# RZN2L register map
Vendor: Renesas Electronics Corporation; Series: RZN; File version: 1.30.01
CPU: other r0p0, little endian, MPU, no FPU, VTOR, 4 interrupt priority bits, 624 interrupts
Registers are 32-bit, read-write, reset 0x0 unless marked. A register's access mark holds for its fields unless they carry their own. Offsets are from the block's base; [hi:lo] are bit positions; {n}, {i} and the like mark numbered series; 'fields as' and 'values as' point back to an identical list.

## SYSRAM_CTL — System SRAM Control
Base 0x81281800
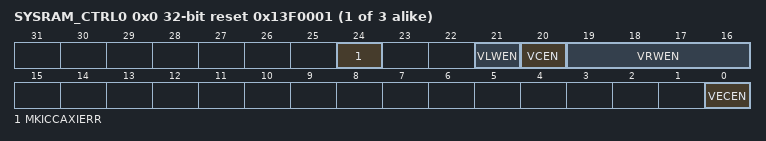
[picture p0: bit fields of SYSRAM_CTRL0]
{0x0+0x10*i} SYSRAM_CTRL{i} (i=0..2) reset 0x13F0001 — System SRAM Control Register {i}
  [24] MKICCAXIERR — Controls AXI-SLVERR issuance for ECC 2-bit errors
    0=Issue AXI-SLEVER; 1=Do not issue AXI-SLEVER
  [21] VLWEN — Enables write for RAM
    0=Disabled; 1=Enabled
  [20] VCEN — Enables access to RAM
    0=Disabled; 1=Enabled
  [19:16] VRWEN — Enables write for each page of RAM
    0=Disabled; 1=Enabled
  [0] VECEN — Enables or disables error correction with ECC
    0=Disabled; 1=Enabled

## SHOSTIF_CFG — Serial Host Interface Configuration
Base 0x81281920
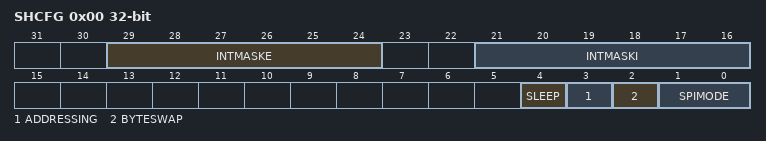
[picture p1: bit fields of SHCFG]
0x00 SHCFG — SHOSTIF Configuration Register
  [29:24] INTMASKE — Interrupt Mask Enable for External Interrupt (HSPI_INT# signal)
    0=No masked; 1=Masked
  [21:16] INTMASKI — Interrupt Mask Enable for Internal Interrupt (SHOST_INT)
    0=No masked; 1=Masked
  [4] SLEEP ro — SHOSTIF Enable Flag Monitor
    0=Not safe to stop the internal clock; 1=Safe to stop the internal clock
  [3] ADDRESSING — Addressing Mode
    0=32-bit; 1=8-bit
  [2] BYTESWAP — Byte Swap Mode
    0=No byte swap. Use this setting if byte order of data input by SPI master is [31:24], [23:16], [15:8], or [7:0].; 1=Byte swap. Use this setting if byte order of data input by SPI master is [7:0], [15:8], [23:16], or [31:24].
  [1:0] SPIMODE — SPI Frame Format Select
    0=Standard SPI mode; 1=SPI Dual mode; 2=SPI Quad mode; 3=SPI Octal mode

## PHOSTIF_CFG — Parallel Host Interface Configuration
Base 0x81281930
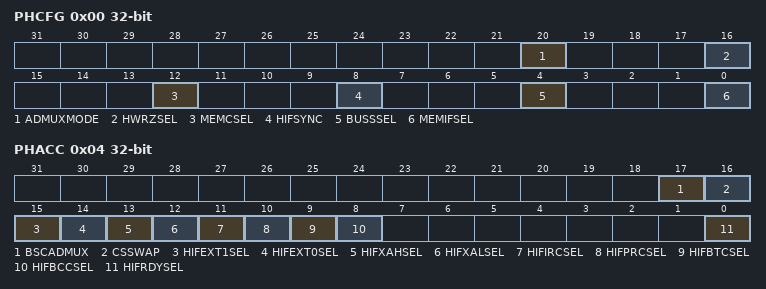
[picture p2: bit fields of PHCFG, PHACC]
0x00 PHCFG — PHOSTIF Configureation Register
  [20] ADMUXMODE
  [16] HWRZSEL
    0=HWRSTB# is write strobe and HWR[1:0] is byte write enable; 1=HWR[1:0]# is byte write strobe. HWRSTB# is not referred.
  [12] MEMCSEL
    0=Synchronous/Asynchronous SRAM interface mode; 1=Synchronous burst SRAM type transfer mode
  [8] HIFSYNC
  [4] BUSSSEL
    0=8-bit bus width; 1=16-bit bus width
  [0] MEMIFSEL
    0=Disables PHOSTIF; 1=Enables PHOSTIF
0x04 PHACC — PHOSTIF Register Access Control Register
  [17] BSCADMUX
    0=Disables; 1=Enables
  [16] CSSWAP
    0=Not swapped; 1=Swapped. HCS0# pin works as HCS1# function and HCS1# pin works as HCS0# function.
  [15] HIFEXT1SEL
    0=Read only; 1=Read and Write
  [14] HIFEXT0SEL
    0=Read only; 1=Read and Write
  [13] HIFXAHSEL
    0=Read only; 1=Read and Write
  [12] HIFXALSEL
    0=Read only; 1=Read and Write
  [11] HIFIRCSEL
    0=Read only; 1=Read and Write
  [10] HIFPRCSEL
    0=Read only; 1=Read and Write
  [9] HIFBTCSEL
    0=Read only; 1=Read and Write
  [8] HIFBCCSEL
    0=Read only; 1=Read and Write
  [0] HIFRDYSEL
    0=HIFRDY bit in HIFMON1 register indicates 0 after PHOSTIF module reset is released. Internal CPU must write 1 to HIFRDY bit in the HIFMON1 register after initial setting of PHOSTIF is completed by internal CPU.; 1=HIFRDY bit in HIFMON1 register indicates 1 after PHOSTIF module reset is released

## RWP_S — Register Write Protection for Safety Area
Base 0x81281A00
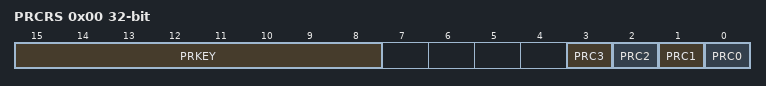
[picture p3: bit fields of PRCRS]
0x00 PRCRS — Safety Area Protect Register
  [15:8] PRKEY wo — PRC Key Code
  [n] PRC{n} (n=0..3) — Protect {n}
    0=Write disabled; 1=Write enabled

## MTU_NF — Multi-Function Timer Pulse Unit Noise Filter
Base 0x90001290
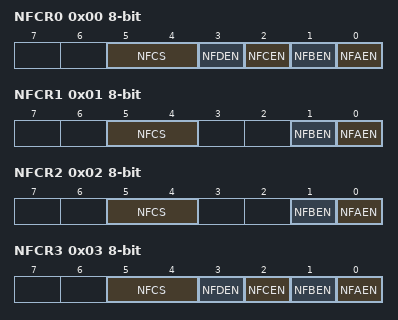
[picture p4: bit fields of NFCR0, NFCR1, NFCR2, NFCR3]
0x00 NFCR0 8-bit — Noise Filter Control Register 0
  [5:4] NFCS — Noise Filter Clock Select
    0=PCLKH/1; 1=PCLKH/8; 2=PCLKH/32; 3=Clock source for counting
  [3] NFDEN — Noise Filter D Enable
    0=The noise filter for the MTIOCnD pin is disabled; 1=The noise filter for the MTIOCnD pin is enabled
  [2] NFCEN — Noise Filter C Enable
    0=The noise filter for the MTIOCnC pin is disabled; 1=The noise filter for the MTIOCnC pin is enabled
  [1] NFBEN — Noise Filter B Enable
    0=The noise filter for the MTIOCnB pin is disabled; 1=The noise filter for the MTIOCnB pin is enabled
  [0] NFAEN — Noise Filter A Enable
    0=The noise filter for the MTIOCnA pin is disabled; 1=The noise filter for the MTIOCnA pin is enabled
0x01 NFCR1 8-bit — Noise Filter Control Register 1
  [5:4] NFCS — Noise Filter Clock Select
    values as NFCR0.NFCS
  [1] NFBEN — Noise Filter B Enable
    0=The noise filter for the MTIOCmB pin is disabled; 1=The noise filter for the MTIOCmB pin is enabled
  [0] NFAEN — Noise Filter A Enable
    0=The noise filter for the MTIOCmA pin is disabled; 1=The noise filter for the MTIOCmA pin is enabled
0x02 NFCR2 8-bit — Noise Filter Control Register 2
  fields as NFCR1
0x03 NFCR3 8-bit — Noise Filter Control Register 3
  fields as NFCR0
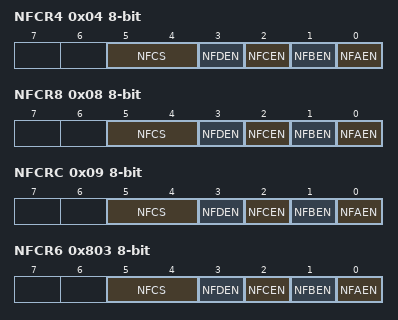
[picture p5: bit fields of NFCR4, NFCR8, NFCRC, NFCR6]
0x04 NFCR4 8-bit — Noise Filter Control Register 4
  fields as NFCR0
0x08 NFCR8 8-bit — Noise Filter Control Register 8
  fields as NFCR0
0x09 NFCRC 8-bit — Noise Filter Control Register C
  [5:4] NFCS — Noise Filter Clock Select
    0=PCLKH/1; 1=PCLKH/2; 2=PCLKH/8; 3=PCLKH/32
  [3] NFDEN — Noise Filter D Enable
    0=The noise filter for the MTCLKD pin is disabled; 1=The noise filter for the MTCLKD pin is enabled
  [2] NFCEN — Noise Filter C Enable
    0=The noise filter for the MTCLKC pin is disabled; 1=The noise filter for the MTCLKC pin is enabled
  [1] NFBEN — Noise Filter B Enable
    0=The noise filter for the MTCLKB pin is disabled; 1=The noise filter for the MTCLKB pin is enabled
  [0] NFAEN — Noise Filter A Enable
    0=The noise filter for the MTCLKA pin is disabled; 1=The noise filter for the MTCLKA pin is enabled
0x803 NFCR6 8-bit — Noise Filter Control Register 6
  fields as NFCR0
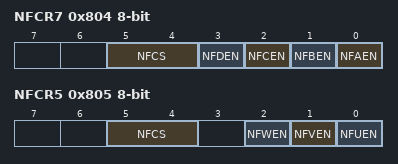
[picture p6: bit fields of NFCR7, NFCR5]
0x804 NFCR7 8-bit — Noise Filter Control Register 7
  fields as NFCR0
0x805 NFCR5 8-bit — Noise Filter Control Register 5
  [5:4] NFCS — Noise Filter Clock Select
    values as NFCR0.NFCS
  [2] NFWEN — Noise Filter W Enable
    0=The noise filter for the MTIC5W pin is disabled; 1=The noise filter for the MTIC5W pin is enabled
  [1] NFVEN — Noise Filter V Enable
    0=The noise filter for the MTIC5V pin is disabled; 1=The noise filter for the MTIC5V pin is enabled
  [0] NFUEN — Noise Filter U Enable
    0=The noise filter for the MTIC5U pin is disabled; 1=The noise filter for the MTIC5U pin is enabled
